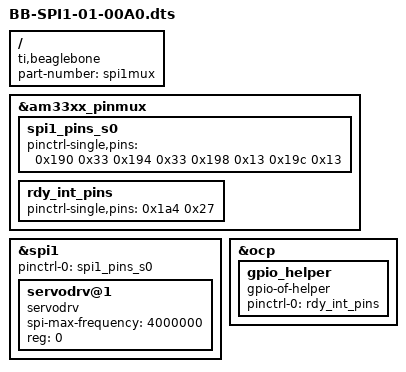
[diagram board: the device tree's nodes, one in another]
/dts-v1/;
/plugin/;

/* SERVO DRIVER */
/* D1 Output and D0 Input */

/ {
    compatible = "ti,beaglebone", "ti,beaglebone-black";

    /* identification */
    part-number = "spi1mux";

    fragment@0 {
        target = <&am33xx_pinmux>;
        __overlay__ {
            spi1_pins_s0: spi1_pins_s0 {
                        pinctrl-single,pins = <
                                0x190 0x33      /* P9_31 mcasp0_aclkx.spi1_sclk, INPUT_PULLUP | MODE3 */
                                0x194 0x33      /* P9_29 mcasp0_fsx.spi1_d0, INPUT_PULLUP | MODE3 */
                                0x198 0x13      /* P9_30 mcasp0_axr0.spi1_d1, OUTPUT_PULLUP | MODE3 */
                                0x19c 0x13      /* P9_28 mcasp0_ahclkr.spi1_cs0, OUTPUT_PULLUP | MODE3 */
                >;
            };
        };
    };
    fragment@1 {
        target = <&am33xx_pinmux>;
        __overlay__ {
            rdy_int_pins: rdy_int_pins {
                        pinctrl-single,pins = <
                                0x1a4 0x27      /* P9_27 gpio, INPUT PULLDOWN | MODE7 for interrupt */
                >;
            };
        };
    };
    
    fragment@2 {
        target = <&spi1>;
        __overlay__ {

             #address-cells = <1>;
             #size-cells = <0>;
             status = "okay";
             pinctrl-names = "default";
             pinctrl-0 = <&spi1_pins_s0>;

             servodrv@1 {
                 spi-max-frequency = <4000000>;
                 reg = <0>;
                 compatible = "servodrv";
            };
        };
    };

    fragment@3 {
		target = <&ocp>;
		__overlay__ {
			gpio_helper {
				compatible = "gpio-of-helper";
				status = "okay";
				pinctrl-names = "default";
				pinctrl-0 = <&rdy_int_pins>;
			};
		};
	};
};
